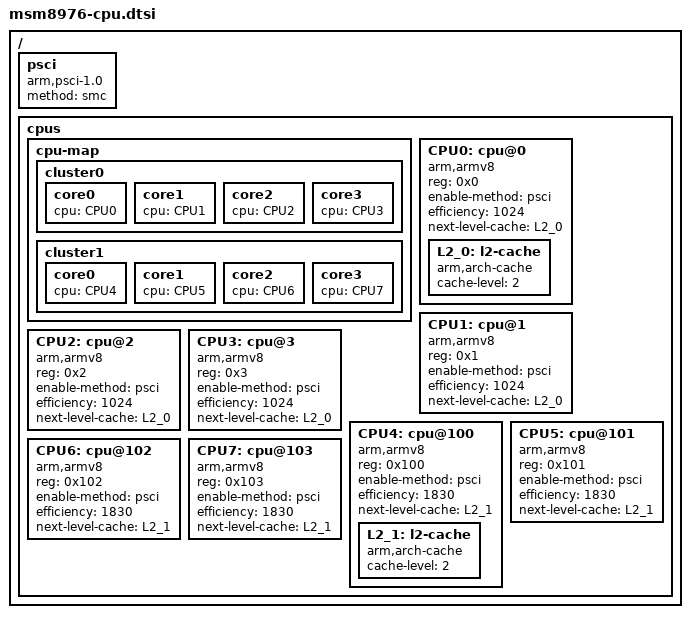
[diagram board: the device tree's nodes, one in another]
// SPDX-License-Identifier: GPL-2.0
// Copyright (c) 2015, The Linux Foundation. All rights reserved.
// Copyright (c) 2023, Benarji Anand <benarji385@gmail.com>

/ {

	psci {
		compatible = "arm,psci-1.0";
		method = "smc";
	};

	cpus {
		#address-cells = <1>;
		#size-cells = <0>;
		cpu-map {
			cluster0 {
				core0 {
					cpu = <&CPU0>;
				};
				core1 {
					cpu = <&CPU1>;
				};
				core2 {
					cpu = <&CPU2>;
				};
				core3 {
					cpu = <&CPU3>;
				};
			};

			cluster1 {
				core0 {
					cpu = <&CPU4>;
				};
				core1 {
					cpu = <&CPU5>;
				};
				core2 {
					cpu = <&CPU6>;
				};
				core3 {
					cpu = <&CPU7>;
				};
			};
		};

		CPU0: cpu@0 {
			device_type = "cpu";
			compatible = "arm,armv8";
			reg = <0x0>;
			enable-method = "psci";
			efficiency = <1024>;
			next-level-cache = <&L2_0>;
			L2_0: l2-cache {
			      compatible = "arm,arch-cache";
			      cache-level = <2>;
			};
		};

		CPU1: cpu@1 {
			device_type = "cpu";
			compatible = "arm,armv8";
			reg = <0x1>;
			enable-method = "psci";
			efficiency = <1024>;
			next-level-cache = <&L2_0>;
		};

		CPU2: cpu@2 {
			device_type = "cpu";
			compatible = "arm,armv8";
			reg = <0x2>;
			enable-method = "psci";
			efficiency = <1024>;
			next-level-cache = <&L2_0>;
		};

		CPU3: cpu@3 {
			device_type = "cpu";
			compatible = "arm,armv8";
			reg = <0x3>;
			enable-method = "psci";
			efficiency = <1024>;
			next-level-cache = <&L2_0>;
		};

		CPU4: cpu@100 {
			device_type = "cpu";
			compatible = "arm,armv8";
			reg = <0x100>;
			enable-method = "psci";
			efficiency = <1830>;
			next-level-cache = <&L2_1>;
			L2_1: l2-cache {
			      compatible = "arm,arch-cache";
			      cache-level = <2>;
			};
		};

		CPU5: cpu@101 {
			device_type = "cpu";
			compatible = "arm,armv8";
			reg = <0x101>;
			enable-method = "psci";
			efficiency = <1830>;
			next-level-cache = <&L2_1>;
		};

		CPU6: cpu@102 {
			device_type = "cpu";
			compatible = "arm,armv8";
			reg = <0x102>;
			enable-method = "psci";
			efficiency = <1830>;
			next-level-cache = <&L2_1>;
		};

		CPU7: cpu@103 {
			device_type = "cpu";
			compatible = "arm,armv8";
			reg = <0x103>;
			enable-method = "psci";
			efficiency = <1830>;
			next-level-cache = <&L2_1>;
		};
	};
};
